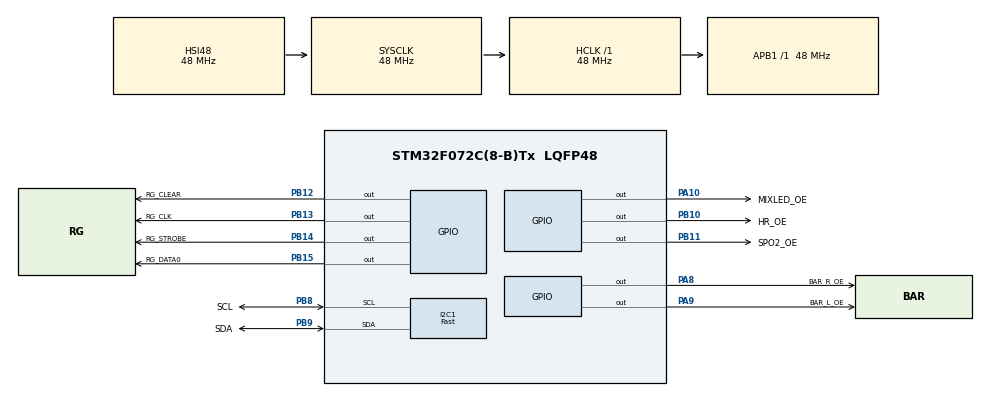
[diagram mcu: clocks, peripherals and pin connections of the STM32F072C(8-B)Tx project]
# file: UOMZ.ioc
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FREERTOS.BinarySemaphores01=semaphoreDisplay,Static,semaphoreDisplayControlBlock
FREERTOS.HEAP_NUMBER=1
FREERTOS.INCLUDE_eTaskGetState=0
FREERTOS.INCLUDE_uxTaskGetStackHighWaterMark=0
FREERTOS.INCLUDE_uxTaskPriorityGet=0
FREERTOS.INCLUDE_vTaskDelete=0
FREERTOS.INCLUDE_vTaskPrioritySet=0
FREERTOS.INCLUDE_vTaskSuspend=0
FREERTOS.INCLUDE_xQueueGetMutexHolder=0
FREERTOS.INCLUDE_xTaskGetSchedulerState=0
FREERTOS.INCLUDE_xTimerPendFunctionCall=0
FREERTOS.Mutexes01=mutexLux,Static,mutexLuxControlBlock;mutexI2c,Static,mutexI2cControlBlock;mutexVoltage,Static,mutexVoltageControlBlock
FREERTOS.Tasks01=taskDisplay,40,64,taskDisplayFunction,As weak,NULL,Static,taskDisplayBuffer,taskDisplayControlBlock;taskLux,24,64,taskLuxFunction,As weak,NULL,Static,taskLuxBuffer,taskLuxControlBlock;taskVoltage,24,64,taskVoltageFunction,As weak,NULL,Static,taskVoltageBuffer,taskVoltageControlBlock
FREERTOS.configMINIMAL_STACK_SIZE=64
FREERTOS.configTIMER_TASK_STACK_DEPTH=64
FREERTOS.configTOTAL_HEAP_SIZE=1024
FREERTOS.configUSE_NEWLIB_REENTRANT=1
FREERTOS.configUSE_TASK_NOTIFICATIONS=1
FREERTOS.configUSE_TRACE_FACILITY=0
I2C1.I2C_Speed_Mode=I2C_Fast
I2C1.Timing=0x0000020B
Mcu.Family=STM32F0
Mcu.Name=STM32F072C(8-B)Tx
Mcu.Package=LQFP48
NVIC.I2C1_IRQn=true\:3\:0\:false\:false\:true\:true\:true\:true\:true
NVIC.TIM7_IRQn=true\:3\:0\:false\:false\:true\:true\:true\:true\:true
PA10.GPIO_Label=MIXLED_OE
PA10.GPIO_Speed=GPIO_SPEED_FREQ_HIGH
PA10.PinState=GPIO_PIN_SET
PA10.Signal=GPIO_Output
PA13.Mode=Serial_Wire
PA13.Signal=SYS_SWDIO
PA14.Mode=Serial_Wire
PA14.Signal=SYS_SWCLK
PA8.GPIO_Label=BAR_R_OE
PA8.GPIO_Speed=GPIO_SPEED_FREQ_HIGH
PA8.PinState=GPIO_PIN_SET
PA8.Signal=GPIO_Output
PA9.GPIO_Label=BAR_L_OE
PA9.GPIO_Speed=GPIO_SPEED_FREQ_HIGH
PA9.PinState=GPIO_PIN_SET
PA9.Signal=GPIO_Output
PB10.GPIO_Label=HR_OE
PB10.GPIO_Speed=GPIO_SPEED_FREQ_HIGH
PB10.Signal=GPIO_Output
PB11.GPIO_Label=SPO2_OE
PB11.GPIO_Speed=GPIO_SPEED_FREQ_HIGH
PB11.Signal=GPIO_Output
PB12.GPIO_Label=RG_CLEAR
PB12.GPIO_Speed=GPIO_SPEED_FREQ_HIGH
PB12.PinState=GPIO_PIN_SET
PB12.Signal=GPIO_Output
PB13.GPIO_Label=RG_CLK
PB13.GPIO_Speed=GPIO_SPEED_FREQ_HIGH
PB13.Signal=GPIO_Output
PB14.GPIO_Label=RG_STROBE
PB14.GPIO_Speed=GPIO_SPEED_FREQ_HIGH
PB14.Signal=GPIO_Output
PB15.GPIO_Label=RG_DATA0
PB15.GPIO_Speed=GPIO_SPEED_FREQ_HIGH
PB15.Signal=GPIO_Output
PB8.GPIO_FM8=SYSCFG_CFGR1_I2C_FMP_PB8
PB8.GPIO_Label=SCL
PB8.Mode=I2C
PB8.Signal=I2C1_SCL
PB9.GPIO_FM9=SYSCFG_CFGR1_I2C_FMP_PB9
PB9.GPIO_Label=SDA
PB9.GPIO_Speed=GPIO_SPEED_FREQ_HIGH
PB9.Mode=I2C
PB9.Signal=I2C1_SDA
ProjectManager.HeapSize=0x200
ProjectManager.StackSize=0x400
ProjectManager.TargetToolchain=STM32CubeIDE
RCC.AHBFreq_Value=48000000
RCC.APB1Freq_Value=48000000
RCC.APB1TimFreq_Value=48000000
RCC.HCLKFreq_Value=48000000
RCC.PLLSourceVirtual=RCC_PLLSOURCE_HSI48
RCC.SYSCLKFreq_VALUE=48000000
RCC.SYSCLKSource=RCC_SYSCLKSOURCE_HSI48
TIM7.AutoReloadPreload=TIM_AUTORELOAD_PRELOAD_ENABLE
TIM7.Period=5
TIM7.Prescaler=0
VP_FREERTOS_VS_CMSIS_V2.Mode=CMSIS_V2
VP_TIM7_VS_ClockSourceINT.Mode=Enable_Timer
board=custom

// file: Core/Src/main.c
/* USER CODE BEGIN Header */
/**
  ******************************************************************************
  * @file           : main.c
  * @brief          : Main program body
  ******************************************************************************
  * @attention
  *
  * Copyright (c) 2023 STMicroelectronics.
  * All rights reserved.
  *
  * This software is licensed under terms that can be found in the LICENSE file
  * in the root directory of this software component.
  * If no LICENSE file comes with this software, it is provided AS-IS.
  *
  ******************************************************************************
  */
/* USER CODE END Header */
#include "main.h"
#include "cmsis_os.h"
#include "i2c.h"
#include "tim.h"
#include "gpio.h"

/* USER CODE BEGIN Includes */
#include "voltage.h"
#include "lux.h"
#include "display.h"
/* USER CODE END Includes */

void SystemClock_Config(void);
void MX_FREERTOS_Init(void);

int main(void)
{

  /* MCU Configuration--------------------------------------------------------*/

  /* Reset of all peripherals, Initializes the Flash interface and the Systick. */
  HAL_Init();

  /* Configure the system clock */
  SystemClock_Config();

  /* Initialize all configured peripherals */
  MX_GPIO_Init();
  MX_TIM7_Init();
  MX_I2C1_Init();

  /* Init scheduler */
  osKernelInitialize();  /* Call init function for freertos objects (in freertos.c) */
  MX_FREERTOS_Init();

  /* Start scheduler */
  osKernelStart();

  /* We should never get here as control is now taken by the scheduler */
  /* Infinite loop */
  while (1)
  {

  }
}

void SystemClock_Config(void)
{
  RCC_OscInitTypeDef RCC_OscInitStruct = {0};
  RCC_ClkInitTypeDef RCC_ClkInitStruct = {0};
  RCC_PeriphCLKInitTypeDef PeriphClkInit = {0};

  /** Initializes the RCC Oscillators according to the specified parameters
  * in the RCC_OscInitTypeDef structure.
  */
  RCC_OscInitStruct.OscillatorType = RCC_OSCILLATORTYPE_HSI|RCC_OSCILLATORTYPE_HSI48;
  RCC_OscInitStruct.HSIState = RCC_HSI_ON;
  RCC_OscInitStruct.HSI48State = RCC_HSI48_ON;
  RCC_OscInitStruct.HSICalibrationValue = RCC_HSICALIBRATION_DEFAULT;
  RCC_OscInitStruct.PLL.PLLState = RCC_PLL_NONE;
  if (HAL_RCC_OscConfig(&RCC_OscInitStruct) != HAL_OK)
  {
    Error_Handler();
  }

  /** Initializes the CPU, AHB and APB buses clocks
  */
  RCC_ClkInitStruct.ClockType = RCC_CLOCKTYPE_HCLK|RCC_CLOCKTYPE_SYSCLK
                              |RCC_CLOCKTYPE_PCLK1;
  RCC_ClkInitStruct.SYSCLKSource = RCC_SYSCLKSOURCE_HSI48;
  RCC_ClkInitStruct.AHBCLKDivider = RCC_SYSCLK_DIV1;
  RCC_ClkInitStruct.APB1CLKDivider = RCC_HCLK_DIV1;

  if (HAL_RCC_ClockConfig(&RCC_ClkInitStruct, FLASH_LATENCY_1) != HAL_OK)
  {
    Error_Handler();
  }
  PeriphClkInit.PeriphClockSelection = RCC_PERIPHCLK_I2C1;
  PeriphClkInit.I2c1ClockSelection = RCC_I2C1CLKSOURCE_HSI;
  if (HAL_RCCEx_PeriphCLKConfig(&PeriphClkInit) != HAL_OK)
  {
    Error_Handler();
  }
}

void Error_Handler(void)
{
  __disable_irq();
  while (1)
  {
  }
}

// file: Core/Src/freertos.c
/* USER CODE BEGIN Header */
/**
  ******************************************************************************
  * File Name          : freertos.c
  * Description        : Code for freertos applications
  ******************************************************************************
  * @attention
  *
  * Copyright (c) 2023 STMicroelectronics.
  * All rights reserved.
  *
  * This software is licensed under terms that can be found in the LICENSE file
  * in the root directory of this software component.
  * If no LICENSE file comes with this software, it is provided AS-IS.
  *
  ******************************************************************************
  */
/* USER CODE END Header */

#include "FreeRTOS.h"
#include "task.h"
#include "main.h"
#include "cmsis_os.h"

typedef StaticTask_t osStaticThreadDef_t;
typedef StaticSemaphore_t osStaticMutexDef_t;
typedef StaticSemaphore_t osStaticSemaphoreDef_t;

/* Definitions for taskDisplay */
osThreadId_t taskDisplayHandle;
uint32_t taskDisplayBuffer[ 64 ];
osStaticThreadDef_t taskDisplayControlBlock;
const osThreadAttr_t taskDisplay_attributes = {
  .name = "taskDisplay",
  .cb_mem = &taskDisplayControlBlock,
  .cb_size = sizeof(taskDisplayControlBlock),
  .stack_mem = &taskDisplayBuffer[0],
  .stack_size = sizeof(taskDisplayBuffer),
  .priority = (osPriority_t) osPriorityHigh,
};
/* Definitions for taskLux */
osThreadId_t taskLuxHandle;
uint32_t taskLuxBuffer[ 64 ];
osStaticThreadDef_t taskLuxControlBlock;
const osThreadAttr_t taskLux_attributes = {
  .name = "taskLux",
  .cb_mem = &taskLuxControlBlock,
  .cb_size = sizeof(taskLuxControlBlock),
  .stack_mem = &taskLuxBuffer[0],
  .stack_size = sizeof(taskLuxBuffer),
  .priority = (osPriority_t) osPriorityNormal,
};
/* Definitions for taskVoltage */
osThreadId_t taskVoltageHandle;
uint32_t taskVoltageBuffer[ 64 ];
osStaticThreadDef_t taskVoltageControlBlock;
const osThreadAttr_t taskVoltage_attributes = {
  .name = "taskVoltage",
  .cb_mem = &taskVoltageControlBlock,
  .cb_size = sizeof(taskVoltageControlBlock),
  .stack_mem = &taskVoltageBuffer[0],
  .stack_size = sizeof(taskVoltageBuffer),
  .priority = (osPriority_t) osPriorityNormal,
};
/* Definitions for mutexLux */
osMutexId_t mutexLuxHandle;
osStaticMutexDef_t mutexLuxControlBlock;
const osMutexAttr_t mutexLux_attributes = {
  .name = "mutexLux",
  .cb_mem = &mutexLuxControlBlock,
  .cb_size = sizeof(mutexLuxControlBlock),
};
/* Definitions for mutexI2c */
osMutexId_t mutexI2cHandle;
osStaticMutexDef_t mutexI2cControlBlock;
const osMutexAttr_t mutexI2c_attributes = {
  .name = "mutexI2c",
  .cb_mem = &mutexI2cControlBlock,
  .cb_size = sizeof(mutexI2cControlBlock),
};
/* Definitions for mutexVoltage */
osMutexId_t mutexVoltageHandle;
osStaticMutexDef_t mutexVoltageControlBlock;
const osMutexAttr_t mutexVoltage_attributes = {
  .name = "mutexVoltage",
  .cb_mem = &mutexVoltageControlBlock,
  .cb_size = sizeof(mutexVoltageControlBlock),
};
/* Definitions for semaphoreDisplay */
osSemaphoreId_t semaphoreDisplayHandle;
osStaticSemaphoreDef_t semaphoreDisplayControlBlock;
const osSemaphoreAttr_t semaphoreDisplay_attributes = {
  .name = "semaphoreDisplay",
  .cb_mem = &semaphoreDisplayControlBlock,
  .cb_size = sizeof(semaphoreDisplayControlBlock),
};

void taskDisplayFunction(void *argument);
void taskLuxFunction(void *argument);
void taskVoltageFunction(void *argument);

void MX_FREERTOS_Init(void); /* (MISRA C 2004 rule 8.1) */

void MX_FREERTOS_Init(void) {
  /* Create the mutex(es) */
  /* creation of mutexLux */
  mutexLuxHandle = osMutexNew(&mutexLux_attributes);

  /* creation of mutexI2c */
  mutexI2cHandle = osMutexNew(&mutexI2c_attributes);

  /* creation of mutexVoltage */
  mutexVoltageHandle = osMutexNew(&mutexVoltage_attributes);

  /* Create the semaphores(s) */
  /* creation of semaphoreDisplay */
  semaphoreDisplayHandle = osSemaphoreNew(1, 1, &semaphoreDisplay_attributes);

  /* Create the thread(s) */
  /* creation of taskDisplay */
  taskDisplayHandle = osThreadNew(taskDisplayFunction, NULL, &taskDisplay_attributes);

  /* creation of taskLux */
  taskLuxHandle = osThreadNew(taskLuxFunction, NULL, &taskLux_attributes);

  /* creation of taskVoltage */
  taskVoltageHandle = osThreadNew(taskVoltageFunction, NULL, &taskVoltage_attributes);

}

__weak void taskDisplayFunction(void *argument)
{
  for(;;)
  {
    osDelay(1);
  }
}

__weak void taskLuxFunction(void *argument)
{
  for(;;)
  {
    osDelay(1);
  }
}

__weak void taskVoltageFunction(void *argument)
{
  for(;;)
  {
    osDelay(1);
  }
}
